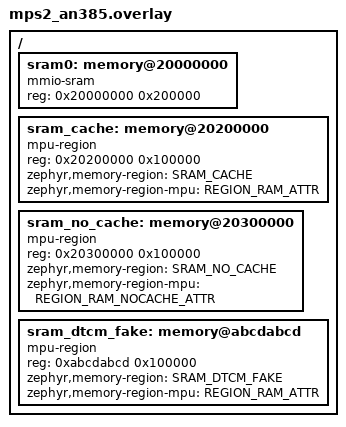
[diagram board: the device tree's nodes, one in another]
/*
 * Copyright (c) 2021 Carlo Caione <ccaione@baylibre.com>
 *
 * SPDX-License-Identifier: Apache-2.0
 */

/ {
	/delete-node/ memory@20000000;

	sram0: memory@20000000 {
		compatible = "mmio-sram";
		reg = <0x20000000 0x200000>;
	};

	sram_cache: memory@20200000 {
		compatible = "mpu-region", "mmio-sram";
		reg = <0x20200000 0x100000>;
		zephyr,memory-region = "SRAM_CACHE";
		zephyr,memory-region-mpu = "REGION_RAM_ATTR";
	};

	sram_no_cache: memory@20300000 {
		compatible = "mpu-region", "mmio-sram";
		reg = <0x20300000 0x100000>;
		zephyr,memory-region = "SRAM_NO_CACHE";
		zephyr,memory-region-mpu = "REGION_RAM_NOCACHE_ATTR";
	};

	sram_dtcm_fake: memory@abcdabcd {
		compatible = "mpu-region", "arm,dtcm";
		reg = <0xabcdabcd 0x100000>;
		zephyr,memory-region = "SRAM_DTCM_FAKE";
		zephyr,memory-region-mpu = "REGION_RAM_ATTR";
	};
};
